# ATA8515 device description
Architecture: AVR8; Family: megaAVR
Registers are 8-bit, access not given, no defined reset value unless marked. A register's access mark holds for its fields unless they carry their own. Offsets are from the block's base; [hi:lo] are bit positions.

## TIMER3
Instances: TIMER3 0x00
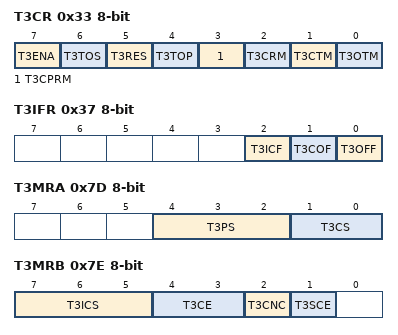
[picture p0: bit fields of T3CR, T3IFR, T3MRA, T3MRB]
0x33 T3CR — Timer3 control Register
  [7] T3ENA — Timer3 Enable
  [6] T3TOS — Timer3 Toggle with Start
  [5] T3RES — Timer3 Reset
  [4] T3TOP — Timer3 Toggle Output Preset
  [3] T3CPRM — Timer3 CaPture reset Mask
  [2] T3CRM — Timer3 Compare Reset Mask
  [1] T3CTM — Timer3 Compare Toggle Mask
  [0] T3OTM — Timer3 Overflow Toggle Mask
0x37 T3IFR — Timer3 interrupt flag Register
  [2] T3ICF — Timer3 Input Capture Flag
  [1] T3COF — Timer3 Compare Flag
  [0] T3OFF — Timer3 OverFlow Flag
0x77 T3CNT 16-bit — Timer3 counter Register
0x79 T3COR 16-bit — Timer3 compare Register
0x7B T3ICR 16-bit — Timer3 input capture Register
0x7D T3MRA — Timer3 mode Register
  [4:2] T3PS — Timer3 Prescaler Select
  [1:0] T3CS — Timer 3 Clock Select
    0=clk_frc; 1=clk_T; 2=clk_xto4; 3=clk_xto2
0x7E T3MRB — Timer3 mode Register
  [7:5] T3ICS — Timer3 Input Capture Select
  [4:3] T3CE — Timer3 Capture Edge select
    0=disable; 1=rising edge; 2=falling edge; 3=both edges
  [2] T3CNC — Timer3 input Capture Noise Canceller
  [1] T3SCE — Timer3 Software Capture Enable
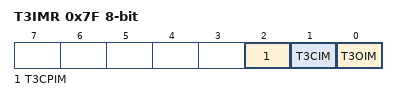
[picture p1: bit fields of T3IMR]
0x7F T3IMR — Timer3 interrupt mask Register
  [2] T3CPIM — Timer3 Capture Interrupt Mask
  [1] T3CIM — Timer3 Compare Interrupt Mask
  [0] T3OIM — Timer3 Overflow Interrupt Mask

## TIMER4
Instances: TIMER4 0x00
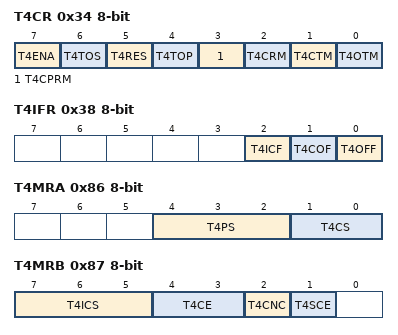
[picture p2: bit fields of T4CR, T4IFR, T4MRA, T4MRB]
0x34 T4CR — Timer4 control Register
  [7] T4ENA — Timer4 Enable
  [6] T4TOS — Timer4 Toggle with Start
  [5] T4RES — Timer4 Reset
  [4] T4TOP — Timer4 Toggle Output Preset
  [3] T4CPRM — Timer4 CaPture reset Mask
  [2] T4CRM — Timer4 Compare Reset Mask
  [1] T4CTM — Timer4 Compare Toggle Mask
  [0] T4OTM — Timer4 Overflow Toggle Mask
0x38 T4IFR — Timer4 interrupt flag Register
  [2] T4ICF — Timer4 Input Capture Flag
  [1] T4COF — Timer4 Compare Flag
  [0] T4OFF — Timer4 OverFlow Flag
0x80 T4CNT 16-bit — Timer4 counter Register
0x82 T4COR 16-bit — Timer4 compare Register
0x84 T4ICR 16-bit — Timer4 input capture Register
0x86 T4MRA — Timer4 mode Register
  [4:2] T4PS — Timer 4 Prescaler Select
  [1:0] T4CS — Timer 4 Clock Select
    0=clk_src; 1=clk_T; 2=clk_xto6; 3=clk_frc
0x87 T4MRB — Timer4 mode Register
  [7:5] T4ICS — Timer4 Input Capture Select
  [4:3] T4CE — Timer4 Capture Edge select
  [2] T4CNC — Timer4 input Capture Noise Canceller
  [1] T4SCE — Timer4 Software Capture Enable
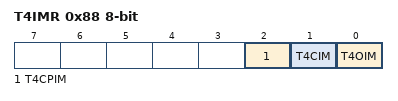
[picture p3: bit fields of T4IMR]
0x88 T4IMR — Timer4 interrupt mask Register
  [2] T4CPIM — Timer4 Capture Interrupt Mask
  [1] T4CIM — Timer4 Compare Interrupt Mask
  [0] T4OIM — Timer4 Overflow Interrupt Mask
Value list TIM4_CAPTURE_EDGE_SELECT: 0=disable; 1=rising edge; 2=falling edge; 3=both edges

## TIMER5
Instances: TIMER5 0x00
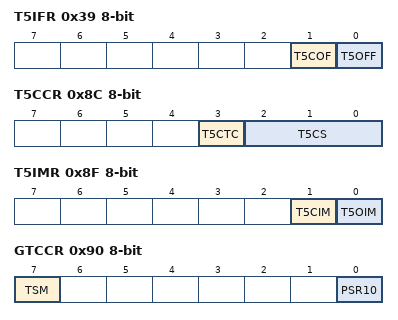
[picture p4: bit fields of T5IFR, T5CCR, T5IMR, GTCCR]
0x39 T5IFR — Timer5 Interrupt Flag Register
  [1] T5COF — Timer5 Output Compare Output Match Flag
  [0] T5OFF — Timer5 Output Overflow Flag
0x8A T5OCR 16-bit — Timer5 Output Compare Register
0x8C T5CCR — Timer5 Control Register
  [3] T5CTC — Clear Timer5 on Compare Match
  [2:0] T5CS — Timer5 Clock Select
    0=No Clock Source (Stopped); 1=Running, No Prescaling; 2=Running, CLK/8; 3=Running, CLK/32; 4=Running, CLK/64; 5=Running, CLK/128; 6=Running, CLK/256; 7=Running, CLK/1024
0x8D T5CNT 16-bit — Timer5 Counter
0x8F T5IMR — Timer5 Interrupt Mask Register
  [1] T5CIM — Timer5 Output Compare Interrupt Mask
  [0] T5OIM — Timer5 Output Overflow Interrupt Mask
0x90 GTCCR — General Timer/Counter Control Register
  [7] TSM — Timer/Counter Synchronization Mode
  [0] PSR10 — PreScaler Reset

## TXM
Instances: TXM 0x00
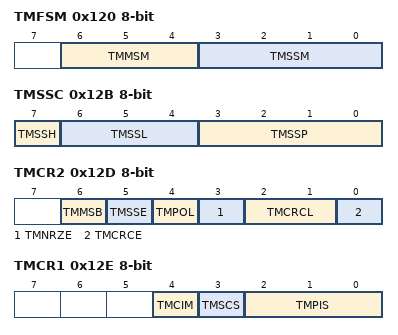
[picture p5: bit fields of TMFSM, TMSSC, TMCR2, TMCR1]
0x120 TMFSM — Tx Modulator Finite State Machine
  [6:4] TMMSM — Tx Modulator Master State Machine
  [3:0] TMSSM — Tx Modulator Sub State Machine
0x121 TMCR 16-bit — Tx Modulator CRC Result
0x123 TMCSB — Tx Modulator CRC Skip Bit Number
0x124 TMCI 16-bit — Tx Modulator CRC Init Value
0x126 TMCP 16-bit — Tx Modulator CRC Polynomial
0x128 TMSHR — Tx Modulator Shift Register
0x129 TMTL 16-bit bits used 11:0 — Tx Modulator Telegram Length Register
0x12B TMSSC — Tx Modulator Stop Sequence Configuration
  [7] TMSSH — Tx Modulator Stop Sequence Hold Mode
  [6:4] TMSSL — Tx Modulator Stop Sequence Length
  [3:0] TMSSP — Tx Modulator Stop Sequence Pattern
0x12C TMSR — Tx Modulator Status Register
  [0] TMTCF — Tx Modulator Transmission Complete Status Flag
0x12D TMCR2 — Tx Modulator Control Register 2
  [6] TMMSB — Tx Modulator Most Significant Bit First
  [5] TMSSE — Tx Modulator Stop Sequence Enable
  [4] TMPOL — Tx Modulator Polarity
  [3] TMNRZE — Tx Modulator NRZ Mode Enable
  [2:1] TMCRCL — Tx Modulator CRC Length
    0=CRC 4-bit; 1=CRC 8-bit; 2=CRC 16-bit
  [0] TMCRCE — Tx Modulator CRC Enable
0x12E TMCR1 — Tx Modulator Control Register 1
  [4] TMCIM — Tx Modulator Transmission Complete Interrupt Mask
  [3] TMSCS — Tx Modulator Serial Output Clock Select
  [2:0] TMPIS — Tx Modulator Port Interface Select
    0=Port C3; 1=M2 - Toggle Register Timer2; 2=M3 - Toggle Register Timer3; 3=M4 - Toggle Register Timer4; 4=SO Tx Modulator Serial Output
